# PIC32MK0512GPH064 device description
Architecture: MIPS; Family: PIC32MK; Series: PIC32MK
Registers are 32-bit, read-write, no defined reset value unless marked. A register's access mark holds for its fields unless they carry their own. Offsets are from the block's base; [hi:lo] are bit positions; {n}, {i} and the like mark numbered series; 'fields as' and 'values as' point back to an identical list.

## JTAG
Instances: JTAG 0x1f801000 in periph_pb1_std
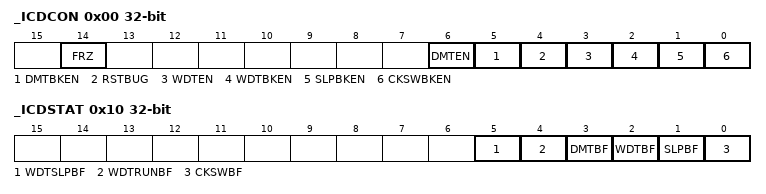
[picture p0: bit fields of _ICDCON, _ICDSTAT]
0x00 _ICDCON
  [14] FRZ, [6] DMTEN, [5] DMTBKEN, [4] RSTBUG, [3] WDTEN, [2] WDTBKEN, [1] SLPBKEN, [0] CKSWBKEN
0x10 _ICDSTAT
  [5] WDTSLPBF, [4] WDTRUNBF, [3] DMTBF, [2] WDTBF, [1] SLPBF, [0] CKSWBF

## NVM
Instances: NVM 0x1f800a00 in periph_pb1_std
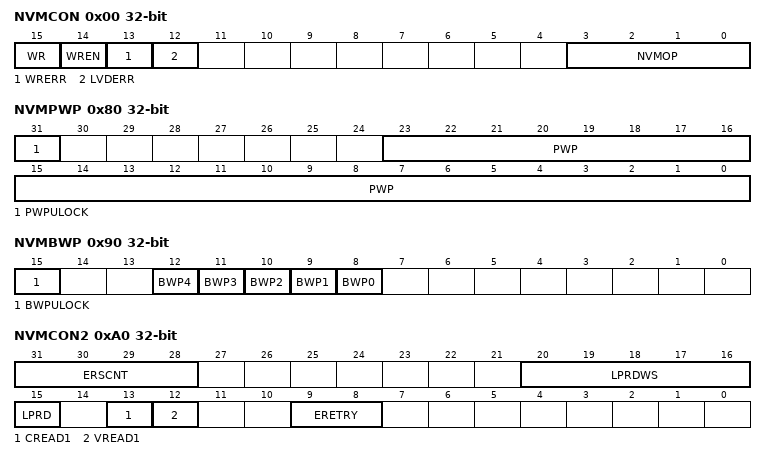
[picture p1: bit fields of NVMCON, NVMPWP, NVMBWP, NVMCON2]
0x00 NVMCON — Flash Programming Control Register
  [15] WR — Write Control bit
    1=Initiate a Flash operation; 0=Flash operation is complete or inactive
  [14] WREN — Write Enable bit
    1=Enable writes to the WR bit and disables writes to the NVMOP bits; 0=Disable writes to WR bit and enables writes to the NVMOP bits
  [13] WRERR — Write Error bit
    1=Program or erase sequence did not complete successfully; 0=Program or erase sequence completed normally
  [12] LVDERR — Low-Voltage Detect Error bit
    1=Low-voltage detected (possible data corruption if WRERR is set); 0=Voltage level is acceptable for programming
  [3:0] NVMOP — NVM Operation bits
    7=Program erase operation: erase all of program Flash memory (all pages must be unprotected); 5=Program Flash memory erase operation: erases all of Program Flash; 4=Page erase operation: erases page selected by NVMADDR; 3=Row program operation: programs row selected by NVMADDR; 2=Quad Word (128-bit) program operation: programs the 128-bit Flash word selected by NVMADDR; 1=Word program operation: programs word selected by NVMADDR; 0=No operation
0x10 NVMKEY wo — Programming Unlock Register
0x20 NVMADDR — Flash Address Register
{0x30+0x10*i} NVMDATA{i} (i=0..3) — Flash Data Register (x = 0-3
0x70 NVMSRCADDR — Source Data Address Register
0x80 NVMPWP — Program Flash Write-Protect Register
  [31] PWPULOCK — Program Flash Memory Page Write-protect Unlock bit
    1=Register is not locked and can be modified; 0=Register is locked and cannot be modified
  [23:0] PWP
0x90 NVMBWP — Flash Boot (Page) Write-Protect Register
  [15] BWPULOCK — Lower Boot Alias Write-protect Unlock bit
    1=LBWPx bits are not locked and can be modified; 0=LBWPx bits are locked and cannot be modified
  [n+8] BWP{n} (n=0..4) — Boot Alias Page {n} Write-protect bit
    1=Write protection for physical address {0x1FC00000+0x4000*n} through {0x1FC03FFF+0x4000*n} enabled; 0=Write protection for physical address {0x1FC00000+0x4000*n} through {0x1FC03FFF+0x4000*n} disabled
0xA0 NVMCON2 — Flash Programming Control Register 2
  [31:28] ERSCNT
  [20:16] LPRDWS — Wait State bits
    {v}={v} Wait States (v=0..31)
  [15] LPRD — Low-Power Read Control bit
    1=Configures Flash for Low Power reads, but with slower higher latency access times; 0=Configures Flash for faster Low Latency reads, but at higher power consumption
  [13] CREAD1 — Compare Read of Logic 1 bit
    1=Selects Erase Retry Procedure with Verify Read; 0=Selects Single Erase w/o Verify Read
  [12] VREAD1 — Verify Read of Logic 1 Control bit
    values as CREAD1
  [9:8] ERETRY — Erase Retry Control bits
    3=Erase strength for last retry cycle; 2=Erase strength for third retry cycle; 1=Erase strength for second retry cycle; 0=Erase strength for first retry cycle

## OCMP
Instances: OCMP 0x1f824000 in periph_pb2_std
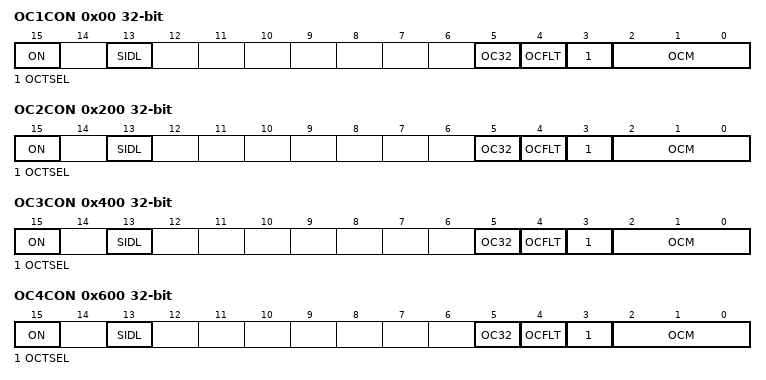
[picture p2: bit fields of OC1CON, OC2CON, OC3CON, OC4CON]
0x00 OC1CON — Output Compare 'x' Control Register
  [15] ON — Output Compare Peripheral On bit
    1=Output Compare peripheral is enabled; 0=Output Compare peripheral is disabled
  [13] SIDL — Stop in Idle Mode bit
    1=Discontinue operation when CPU enters Idle mode; 0=Continue operation in Idle mode
  [5] OC32 — 32-bit Compare Mode bit
    1=OCxR and/or OCxRS are used for comparisions to the 32-bit timer source; 0=OCxR and OCxRS are used for comparisons to the 16-bit timer source
  [4] OCFLT — PWM Fault Condition Status bit
    1=PWM Fault condition has occurred (cleared in HW only); 0=No PWM Fault condition has occurred
  [3] OCTSEL — Output Compare Timer Select bit
    1=Timery is the clock source for this Output Compare module; 0=Timerx is the clock source for this Output Compare module
  [2:0] OCM — Output Compare Mode Select bits
    7=PWM mode on OCx; Fault pin enabled; 6=PWM mode on OCx; Fault pin diabled; 5=Initialize OCx pin low; generate continious output pulses on OCx pin; 4=Initialize OCx pin low: generate single output pulse on OCx pin; 3=Compare event toggles OCx pin; 2=Initialize OCx pin high ; compare event forces OCx pin low; 1=Initialize OCx pin low; compare event forces OCx pin high; 0=Output compare peripheral is disabled but continues to draw current
0x10 OC1R
0x20 OC1RS
0x200 OC2CON — Output Compare 'x' Control Register
  fields as OC1CON
0x210 OC2R
0x220 OC2RS
0x400 OC3CON — Output Compare 'x' Control Register
  fields as OC1CON
0x410 OC3R
0x420 OC3RS
0x600 OC4CON — Output Compare 'x' Control Register
  fields as OC1CON
0x610 OC4R
0x620 OC4RS
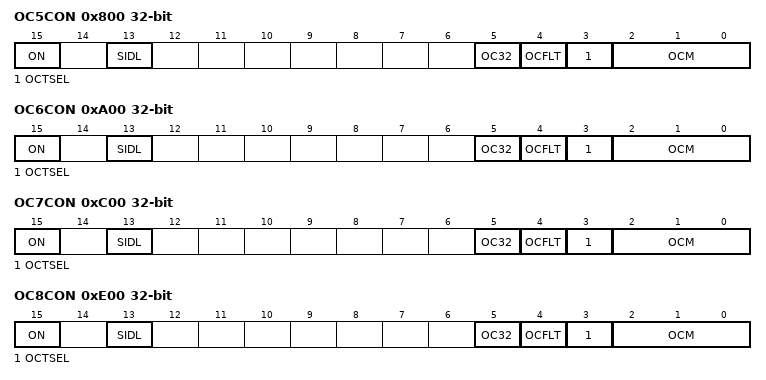
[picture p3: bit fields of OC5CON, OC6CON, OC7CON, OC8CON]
0x800 OC5CON — Output Compare 'x' Control Register
  fields as OC1CON
0x810 OC5R
0x820 OC5RS
0xA00 OC6CON — Output Compare 'x' Control Register
  fields as OC1CON
0xA10 OC6R
0xA20 OC6RS
0xC00 OC7CON — Output Compare 'x' Control Register
  fields as OC1CON
0xC10 OC7R
0xC20 OC7RS
0xE00 OC8CON — Output Compare 'x' Control Register
  fields as OC1CON
0xE10 OC8R
0xE20 OC8RS
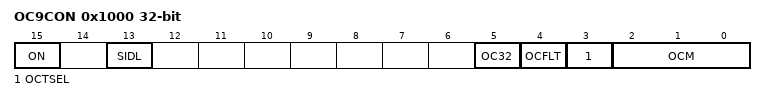
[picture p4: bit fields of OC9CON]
0x1000 OC9CON — Output Compare 'x' Control Register
  fields as OC1CON
0x1010 OC9R
0x1020 OC9RS
